# gpio_wrap: IP-XACT component
VLNV tenstorrent.com:ocah:gpio_wrap:1.0

## Address spaces and blocks
gpio_wrap.gpio_intf: base 'h0, range 'hc, width 32
gpio_wrap.gpio_ctrl: base 'h10, range 'h4, width 32

## Registers
Registers are 32-bit, access per field, reset 0x0 unless marked. A register's access mark holds for its fields unless they carry their own. Offsets are from the block's base; lines under a group give offsets from that group; [hi:lo] are bit positions; {n}, {i} and the like mark numbered series; 'fields as' and 'values as' point back to an identical list; <NAME> marks a mode.

## gpio_wrap.gpio_intf — GPIO interface configuration: pad/core routing, receive and transmit enables, and interrupt control.
Base 0x00000000
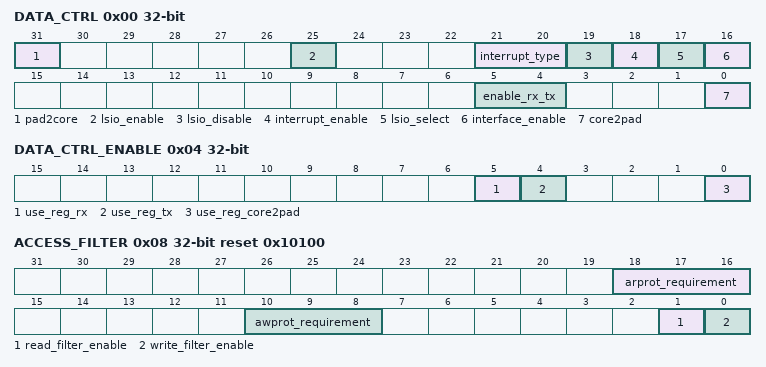
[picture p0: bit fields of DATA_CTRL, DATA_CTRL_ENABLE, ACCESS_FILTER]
0x00 DATA_CTRL
  [31] pad2core ro — PAD2SOC Value
  [25] lsio_enable ro — LSIO hardware request status. Set while lsio_interface_select_i is asserted and lsio_disable is clear. Because the hardware LSIO request outranks interface_enable, a set value also means the LSIO plane is driving this pad's data and direction. This field does not reflect a software-forced selection via lsio_select, which ranks below the register interface - it reads 0 in that case even when LSIO drives the pad.
  [21:20] interrupt_type rw — Interrupt type - 0: active-high level, 1: active-low level, 2: rising edge, 3: falling edge
  [19] lsio_disable rw — When set, LSIO accesses will be blocked from the GPIO interface
  [18] interrupt_enable rw
  [17] lsio_select rw — Force the LSIO interface to be used from software, when no hardware LSIO request is present on this pad. interface_enable has higher priority over this bit. This ranking applies to this software force bit only: the hardware lsio_interface_select_i input outranks interface_enable. Use lsio_disable to gate both.
  [16] interface_enable rw — Register Interface Enable. Setting this chooses register values to drive the PAD. This includes core2pad, enable_rx_tx, and pad2core
  [5:4] enable_rx_tx rw — Direction control. 2'b00: Neither RX nor TX enabled. 2'b01: TX enabled. 2'b10: RX enabled. 2'b11: Both enabled
  [0] core2pad rw — Register-driven data to send to the pad.
0x04 DATA_CTRL_ENABLE rw
  [5] use_reg_rx — Per-field register override. When set, the RX direction (input enable) is taken from enable_rx_tx[1]. OR'd with interface_enable.
  [4] use_reg_tx — Per-field register override. When set, the TX direction (output enable) is taken from enable_rx_tx[0]. OR'd with interface_enable.
  [0] use_reg_core2pad — Per-field register override. When set, core2pad is register-driven. OR'd with interface_enable.
0x08 ACCESS_FILTER rw reset 0x10100 — GPIO Access Filter Register. WARNING: please read back this register to ensure the filter was written correctly. If you do not do so the filter may not update before your next transaction, causing unexpected behavior.
  [18:16] arprot_requirement — When read_filter_enable is set, only allow read accesses with this prot value WARNING: please read back this register to ensure the filter was written correctly. If you do not do so the filter may not update before your next transaction, causing unexpected behavior.
  [10:8] awprot_requirement — When write_filter_enable is set, only allow write accesses with this prot value WARNING: please read back this register to ensure the filter was written correctly. If you do not do so the filter may not update before your next transaction, causing unexpected behavior.
  [1] read_filter_enable — Read Filter Enable. When set, reads require an exact match between AXI ARPROT and arprot_requirement. When clear, reads are unfiltered. PROT does not identify the initiator. WARNING: please read back this register to ensure the filter was written correctly. If you do not do so the filter may not update before your next transaction, causing unexpected behavior.
  [0] write_filter_enable — Write Filter Enable. When set, writes require an exact match between AXI AWPROT and awprot_requirement. When clear, writes are unfiltered. PROT does not identify the initiator. WARNING: please read back this register to ensure the filter was written correctly. If you do not do so the filter may not update before your next transaction, causing unexpected behavior.

## gpio_wrap.gpio_ctrl — Per-pin GPIO pad control registers: drive strength, pull configuration, and strap capture.
Base 0x00000010
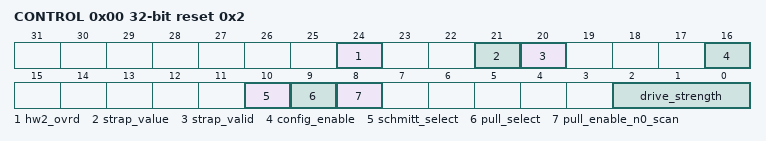
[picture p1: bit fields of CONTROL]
0x00 CONTROL reset 0x2 (reset mask 0x1210707)
  [24] hw2_ovrd rw — Setting this register will enable the secondary HW function to override the GPIO enable and data lines.
  [21] strap_value ro — This register holds the captured value that was applied to the pad when reset was de-asserted.
  [20] strap_valid ro — Reflects the INPUT_BY_DEFAULT parameter of the instance: 1 when the pad is an input by default and strap capture is supported, 0 otherwise. Fixed at integration; not a capture-done or reset-done flag.
  [16] config_enable rw — Setting this choosing the register values for PAD settings. This includes pull_enable, pull_select, and schmitt_select
  [10] schmitt_select rw — Register-driven schmitt select.
  [9] pull_select rw — Register-driven pull select - by default we pull down
  [8] pull_enable_n0_scan rw — Register-driven pull enable. Default is disabled
  [2:0] drive_strength rw — Register-driven drive-strength.

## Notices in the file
SPDX-License-Identifier: Apache-2.0
SPDX-FileCopyrightText: 2026 Tenstorrent USA, Inc.
